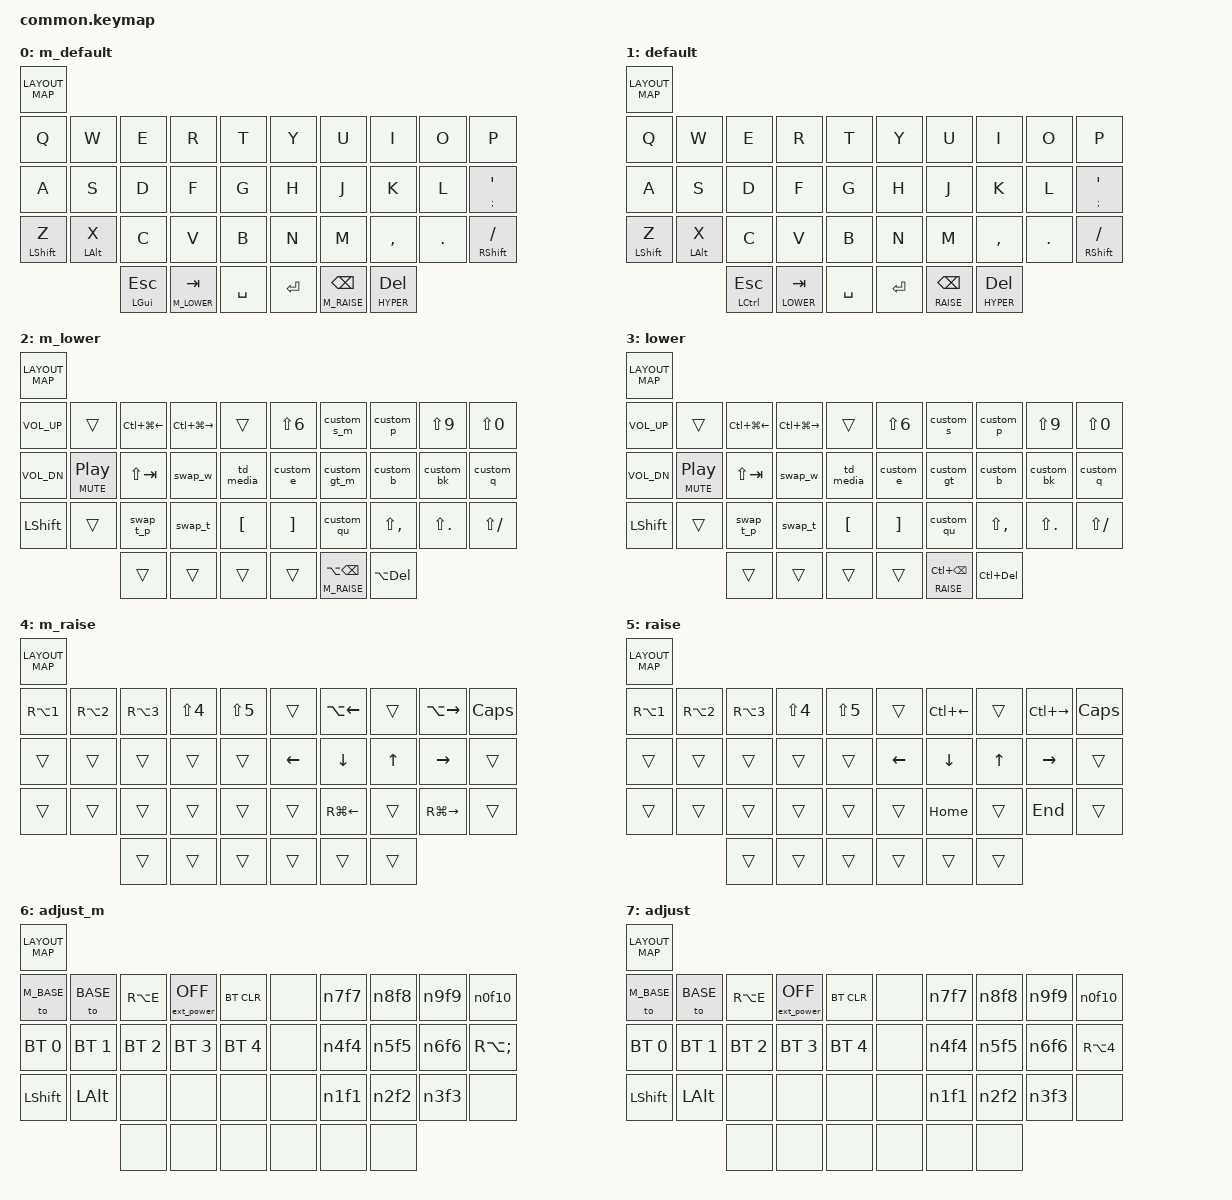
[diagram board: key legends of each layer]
#include <behaviors.dtsi>
#include <dt-bindings/zmk/keys.h>
#include <dt-bindings/zmk/bt.h>
#include <dt-bindings/zmk/ext_power.h>

#define M_BASE 0
#define BASE 1
#define M_LOWER 2
#define LOWER 3
#define M_RAISE 4
#define RAISE 5
#define M_ADJUST 6
#define ADJUST 7

#define HYPER LS(LA(LC(LGUI)))

&lt {
    tapping-term-ms = <200>;
    flavor = "hold-preferred";
};

/ {
    combos {
        compatible = "zmk,combos";
        combo_gui_left {
            timeout-ms = <50>;
            key-positions = <GUI_LEFT>;
            bindings = <&kp LGUI>;
            layers = <BASE>;
        };
        combo_gui_right {
            timeout-ms = <50>;
            key-positions = <GUI_RIGHT>;
            bindings = <&kp LGUI>;
            layers = <BASE>;
        };
        combo_ctrl_left {
            timeout-ms = <50>;
            key-positions = <GUI_LEFT>;
            bindings = <&kp LCTRL>;
            layers = <M_BASE>;
        };
        combo_ctrl_right {
            timeout-ms = <50>;
            key-positions = <GUI_RIGHT>;
            bindings = <&kp LCTRL>;
            layers = <M_BASE>;
        };
    };

    behaviors {
        td_media: tap_dance_media {  
            compatible = "zmk,behavior-tap-dance";  
            #binding-cells = <0>;  
            tapping-term-ms = <200>;  
            bindings = <&kp C_NEXT>, <&kp C_PREV>;
        };
        lp: long_press {
            compatible = "zmk,behavior-hold-tap";
            #binding-cells = <2>;
            flavor = "hold-preferred";
            tapping-term-ms = <200>;
            bindings = <&kp>, <&kp>;
            hold-trigger-key-positions = <1>;
        };
        mt_b: mod_tap_balanced {
            compatible = "zmk,behavior-hold-tap";
            #binding-cells = <2>;
            flavor = "balanced";
            tapping-term-ms = <150>;
            bindings = <&kp>, <&kp>;
        };
        custom_p: custom_parenthesis {
            compatible = "zmk,behavior-mod-morph";
            #binding-cells = <0>;
            bindings = <&kp LS(N8)>, <&kp LS(N9)>;
            mods = <(MOD_LSFT|MOD_RSFT)>;
        };
        custom_gt: custom_gt {
            compatible = "zmk,behavior-mod-morph";
            #binding-cells = <0>;
            bindings = <&kp NUBS>, <&kp LS(NUBS)>;
            mods = <(MOD_LSFT|MOD_RSFT)>;
        };
        custom_gt_m: custom_gt_m {
            compatible = "zmk,behavior-mod-morph";
            #binding-cells = <0>;
            bindings = <&kp GRAVE>, <&kp LS(GRAVE)>;
            mods = <(MOD_LSFT|MOD_RSFT)>;
        };
        custom_bk: custom_bracket {
            compatible = "zmk,behavior-mod-morph";
            #binding-cells = <0>;
            bindings = <&kp RA(LBKT)>, <&kp RA(RBKT)>;
            mods = <(MOD_LSFT|MOD_RSFT)>;
        };
        custom_b: custom_brace {
            compatible = "zmk,behavior-mod-morph";
            #binding-cells = <0>;
            bindings = <&kp RA(SQT)>, <&kp RA(NUHS)>;
            mods = <(MOD_LSFT|MOD_RSFT)>;
        };
        custom_q: custom_question {
            compatible = "zmk,behavior-mod-morph";
            #binding-cells = <0>;
            bindings = <&kp LS(MINUS)>, <&kp PLUS>;
            mods = <(MOD_LSFT|MOD_RSFT)>;
        };
        custom_e: custom_exclamation {
            compatible = "zmk,behavior-mod-morph";
            #binding-cells = <0>;
            bindings = <&kp LS(N1)>, <&kp EQUAL>;
            mods = <(MOD_LSFT|MOD_RSFT)>;
        };
        custom_s: custom_slash {
            compatible = "zmk,behavior-mod-morph";
            #binding-cells = <0>;
            bindings = <&kp LS(N7)>, <&kp RA(GRAVE)>;
            mods = <(MOD_LSFT|MOD_RSFT)>;
        };
        custom_s_m: custom_slash_mac {
            compatible = "zmk,behavior-mod-morph";
            #binding-cells = <0>;
            bindings = <&kp LS(N7)>, <&kp RA(NON_US_BSLH)>;
            mods = <(MOD_LSFT|MOD_RSFT)>;
        };
        custom_qu: custom_quote {
            compatible = "zmk,behavior-mod-morph";
            #binding-cells = <0>;
            bindings = <&kp LS(N2)>, <&kp MINUS>;
            mods = <(MOD_LSFT|MOD_RSFT)>;
        };
        swap_w: tri-state-window {
            compatible = "zmk,behavior-tri-state";
            #binding-cells = <0>;
            bindings = <&kt LALT>, <&kp TAB>, <&kt LALT>;
            ignored-key-positions = <SWAP_W_IGNORED>;
        };
        swap_t: tri-state-tab {
            compatible = "zmk,behavior-tri-state";
            #binding-cells = <0>;
            bindings = <&kt LCTRL>, <&kp TAB>, <&kt LCTRL>;
            ignored-key-positions = <SWAP_T_IGNORED>;
        };
        swap_t_p: tri-state-window-prev {
            compatible = "zmk,behavior-mod-morph";
            #binding-cells = <0>;
            bindings = <&kp LC(LS(TAB))>, <&kp LS(TAB)>;
            mods = <MOD_LCTL>;
            keep-mods = <MOD_LCTL>;
        };
        n1f1: f1_behavior {
            compatible = "zmk,behavior-mod-morph";
            #binding-cells = <0>;
            bindings = <&kp N1>, <&kp F1>;
            mods = <(MOD_LSFT|MOD_RSFT)>;
        };
        n2f2: f2_behavior {
            compatible = "zmk,behavior-mod-morph";
            #binding-cells = <0>;
            bindings = <&kp N2>, <&kp F2>;
            mods = <(MOD_LSFT|MOD_RSFT)>;
        };
        n3f3: f3_behavior {
            compatible = "zmk,behavior-mod-morph";
            #binding-cells = <0>;
            bindings = <&kp N3>, <&kp F3>;
            mods = <(MOD_LSFT|MOD_RSFT)>;
        };
        n4f4: f4_behavior {
            compatible = "zmk,behavior-mod-morph";
            #binding-cells = <0>;
            bindings = <&kp N4>, <&kp F4>;
            mods = <(MOD_LSFT|MOD_RSFT)>;
        };
        n5f5: f5_behavior {
            compatible = "zmk,behavior-mod-morph";
            #binding-cells = <0>;
            bindings = <&kp N5>, <&kp F5>;
            mods = <(MOD_LSFT|MOD_RSFT)>;
        };
        n6f6: f6_behavior {
            compatible = "zmk,behavior-mod-morph";
            #binding-cells = <0>;
            bindings = <&kp N6>, <&kp F6>;
            mods = <(MOD_LSFT|MOD_RSFT)>;
        };
        n7f7: f7_behavior {
            compatible = "zmk,behavior-mod-morph";
            #binding-cells = <0>;
            bindings = <&kp N7>, <&kp F7>;
            mods = <(MOD_LSFT|MOD_RSFT)>;
        };
        n8f8: f8_behavior {
            compatible = "zmk,behavior-mod-morph";
            #binding-cells = <0>;
            bindings = <&kp N8>, <&kp F8>;
            mods = <(MOD_LSFT|MOD_RSFT)>;
        };
        n9f9: f9_behavior {
            compatible = "zmk,behavior-mod-morph";
            #binding-cells = <0>;
            bindings = <&kp N9>, <&kp F9>;
            mods = <(MOD_LSFT|MOD_RSFT)>;
        };
        n0f10: f10_behavior {
            compatible = "zmk,behavior-mod-morph";
            #binding-cells = <0>;
            bindings = <&kp N0>, <&kp F10>;
            mods = <(MOD_LSFT|MOD_RSFT)>;
        };
    };

   // Activate ADJUST layers by pressing raise and lower
    conditional_layers {
        compatible = "zmk,conditional-layers";
        adjust_layer {
            if-layers = <LOWER RAISE>;
            then-layer = <ADJUST>;
        };
        adjust_layer_m {
            if-layers = <M_LOWER M_RAISE>;
            then-layer = <M_ADJUST>;
        };
    };
    keymap {
        compatible = "zmk,keymap";

        default_layer_m {
            display-name = "m_default";
// ----------------------------------------------------------------------------------------------------------------------
// |   Q    |   W    |   E    |   R    |   T    |             |   Y    |   U    |   I    |   O    |   P    |
// |   A    |   S    |   D    |   F    |   G    |             |   H    |   J    |   K    |   L    |   Ñ    |
// |Z/SHIFT |X/ALT   |   C    |   V    |   B    |             |   N    |   M    |   ,    |   .    |-/SHIFT |
//                | CTRL/ESC  | LOWER/TAB |  SPACE   |  ENTER   | RAISE/BKSPC |  DEL   |
            bindings = <LAYOUT_MAP(
&kp Q,&kp W,   &kp E,   &kp R,    &kp T,                           &kp Y, &kp U,    &kp I,    &kp O,   &kp P,
&kp A, &kp S,   &kp D,   &kp F,    &kp G,                          &kp H, &kp J,    &kp K,    &kp L,  &lp SEMI SQT, 
&mt LSHIFT Z,  &mt_b LALT X,    &kp C,   &kp V, &kp B,                 &kp N, &kp M,    &kp COMMA,&kp DOT,  &mt RSHFT FSLH,
                                  &mt LGUI ESC, &lt M_LOWER TAB, &kp SPACE,    &kp RET,  &lt M_RAISE BSPC, &mt HYPER DEL
            )>;
        };

        default_layer {
            display-name = "default";
// ----------------------------------------------------------------------------------------------------------------------
// |   Q    |   W    |   E    |   R    |   T    |             |   Y    |   U    |   I    |   O    |   P    |
// |   A    |   S    |   D    |   F    |   G    |             |   H    |   J    |   K    |   L    |   Ñ    |
// |Z/SHIFT |X/ALT   |   C    |   V    |   B    |             |   N    |   M    |   ,    |   .    |-/SHIFT |
//                | CTRL/ESC  | LOWER/TAB |  SPACE   |  ENTER   | RAISE/BKSPC |  DEL   |
            bindings = <LAYOUT_MAP(
&kp Q, &kp W,    &kp E,    &kp R,     &kp T,                            &kp Y,  &kp U,     &kp I,     &kp O,    &kp P,
&kp A,  &kp S,    &kp D,    &kp F,     &kp G,                           &kp H,  &kp J,     &kp K,     &kp L,   &lp SEMI SQT,
&mt LSHIFT Z,  &mt_b LALT X,    &kp C,    &kp V,  &kp B,                  &kp N,  &kp M,     &kp COMMA, &kp DOT,  &mt RSHFT FSLH,
            &mt LCTRL ESC, &lt LOWER TAB, &kp SPACE,                  &kp RET,  &lt RAISE BSPC, &mt HYPER DEL
            )>;
        };

        lower_layer_m {
            display-name = "m_lower";
// ----------------------------------------------------------------------------------------------------------------------
// | VOLU    |         | PRV_WPC | NXT_WPC |         |             |   &    |   /    |   (    |   )    |   =    |
// | VOLD    |PLAY-MUTE| prev_w  | swap_w  |NXT/PRV  |             |   !    |   <    |   {    |   [    |   ?    |
// | SHIFT   |         | prev_t  | swap_t  |   `     |             |   +    |   '    |   ;    |   :    |   _    |
//                |           |           |         |             |         | WORD_DEL |

            bindings = <LAYOUT_MAP(
&kp C_VOL_UP, &trans,    &kp LC(LG(LEFT)), &kp LC(LG(RIGHT)), &trans,      &kp LS(N6), &custom_s_m,     &custom_p, &kp LS(N9),  &kp LS(N0),
&kp C_VOL_DN, &lp C_MUTE C_PP, &kp LS(TAB), &swap_w,  &td_media,                     &custom_e,  &custom_gt_m, &custom_b, &custom_bk,  &custom_q,
&kp LSHFT, &trans,       &swap_t_p, &swap_t,  &kp LBKT,                        &kp RBKT, &custom_qu, &kp LS(COMMA), &kp LS(DOT), &kp LS(FSLH),
                                       &trans,    &trans,  &trans, &trans,  &lt M_RAISE LA(BSPC),  &kp LA(DEL)
            )>;
        };

        lower_layer {
            display-name = "lower";
// ----------------------------------------------------------------------------------------------------------------------
// | VOLU    |         | PRV_WPC | NXT_WPC |         |             |   &    |   /    |   (    |   )    |   =    |
// | VOLD    |PLAY-MUTE| prev_w  | swap_w  |NXT/PRV  |             |   !    |   <    |   {    |   [    |   ?    |
// | SHIFT   |         | prev_t  | swap_t  |   `     |             |   +    |   '    |   ;    |   :    |   _    |
//                |           |           |         |             |         | WORD_DEL |
            bindings = <LAYOUT_MAP(
&kp C_VOL_UP, &trans,    &kp LC(LG(LEFT)), &kp LC(LG(RIGHT)), &trans,         &kp LS(N6), &custom_s,     &custom_p, &kp LS(N9),  &kp LS(N0),
&kp C_VOL_DN, &lp C_MUTE C_PP, &kp LS(TAB), &swap_w, &td_media,                        &custom_e, &custom_gt,  &custom_b, &custom_bk, &custom_q,
&kp LSHFT, &trans,       &swap_t_p, &swap_t,  &kp LBKT,                          &kp RBKT, &custom_qu, &kp LS(COMMA), &kp LS(DOT), &kp LS(FSLH),
                                   &trans,    &trans,  &trans, &trans,  &lt RAISE LC(BSPC),  &kp LC(DEL)
            )>;
        };

        raise_layer_m {
            display-name = "m_raise";
// ----------------------------------------------------------------------------------------------------------------------
// |        |        |   @    |   #    |   $    |   %    |             |        | PRVWD  |        | NXTWD  | CAPS   |
// |        |        |        |        |        |        |             |  <-    |   v    |   ^    |   ->   |        |
// |        |        |        |        |        |        |             |        | HOME   |        | END    |        |
//                |         |        |        |             |        |        |
            bindings = <LAYOUT_MAP(
&kp RA(N1),   &kp RA(N2),   &kp RA(N3),  &kp LS(N4),   &kp LS(N5),               &trans,     &kp LA(LEFT), &trans,    &kp LA(RIGHT), &kp CAPS,
&trans,       &trans,       &trans,      &trans,       &trans,                   &kp LEFT,   &kp DOWN,   &kp UP, &kp RIGHT,   &trans,
&trans,       &trans,       &trans,      &trans,       &trans,                   &trans,  &kp RG(LEFT),    &trans,   &kp RG(RIGHT),    &trans,
                          &trans,      &trans,       &trans,            &trans,  &trans,    &trans
            )>;
        };

        raise_layer {
            display-name = "raise";
// ----------------------------------------------------------------------------------------------------------------------
// |        |        |   @    |   #    |   $    |   %    |             |        | PRVWD  |        | NXTWD  |        |
// |        |        |        |        |        |        |             |  <-    |   v    |   ^    |   ->   |        |
// |        |        |        |        |        |        |             |        | HOME   |        | END    |        |
//                |         |        |        |             |        |        |
            bindings = <LAYOUT_MAP(
&kp RA(N1),   &kp RA(N2),   &kp RA(N3),  &kp LS(N4),   &kp LS(N5),               &trans,      &kp LC(LEFT), &trans, &kp LC(RIGHT), &kp CAPS,
&trans,       &trans,       &trans,      &trans,       &trans,                   &kp LEFT,     &kp DOWN,   &kp UP, &kp RIGHT,   &trans,
&trans,       &trans,       &trans,      &trans,       &trans,                   &trans,       &kp HOME,   &trans, &kp END,    &trans,
                          &trans,      &trans,       &trans,            &trans,       &trans,    &trans
            )>;
        };

        adjust_layer_m {
// ----------------------------------------------------------------------------------------------------------------------
// |  MAC   |  WIN   |   €    | EXTPWR | BTCLR  |             |   7   |   8   |   9   |   0   |
// |  BT1   |  BT2   |  BT3   |  BT4   |  BT5   |             |   4   |   5   |   6   |   ~   |
// | SHIFT  |  ALT   |        |        |        |             |   1   |   2   |   3   |       |
//                |        |        |        |             |       |       |
            display-name = "adjust_m";
             bindings = <LAYOUT_MAP(
&to M_BASE,   &to BASE,     &kp RA(E),    &ext_power EP_OFF, &bt BT_CLR,                 &none, &n7f7, &n8f8, &n9f9, &n0f10,
&bt BT_SEL 0, &bt BT_SEL 1, &bt BT_SEL 2, &bt BT_SEL 3,  &bt BT_SEL 4,                   &none, &n4f4, &n5f5, &n6f6, &kp RA(SEMI),
&kp LSHIFT,   &kp LALT,     &none,        &none,         &none,                          &none, &n1f1, &n2f2, &n3f3, &none,
                                  &none,   &none,   &none,           &none,  &none, &none
            )>;
        };

        adjust_layer {
// ----------------------------------------------------------------------------------------------------------------------
// |  MAC   |  WIN   |   €    | EXTPWR | BTCLR  |             |   7   |   8   |   9   |   0   |
// |  BT1   |  BT2   |  BT3   |  BT4   |  BT5   |             |   4   |   5   |   6   |   ~   |
// | SHIFT  |  ALT   |        |        |        |             |   1   |   2   |   3   |       |
//                |        |        |        |             |       |       |
            display-name = "adjust";
            bindings = <LAYOUT_MAP(
&to M_BASE,   &to BASE,     &kp RA(E),    &ext_power EP_OFF, &bt BT_CLR,             &none, &n7f7, &n8f8, &n9f9, &n0f10,
&bt BT_SEL 0, &bt BT_SEL 1, &bt BT_SEL 2, &bt BT_SEL 3,  &bt BT_SEL 4,               &none, &n4f4, &n5f5, &n6f6, &kp RA(N4),
&kp LSHIFT,   &kp LALT,     &none,        &none,         &none,                      &none, &n1f1, &n2f2, &n3f3, &none,
                                  &none,   &none,   &none,           &none,  &none, &none
            )>;
        };
    };
};
